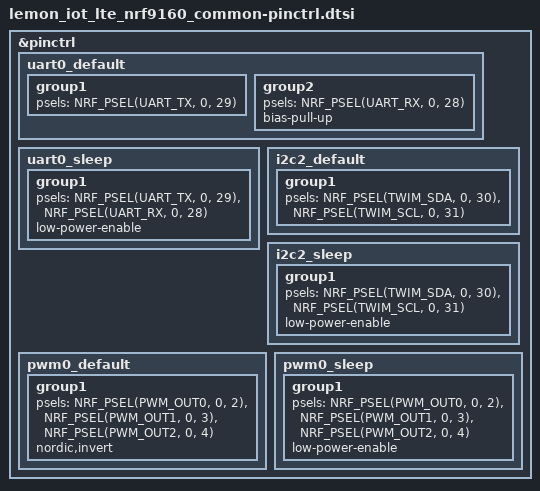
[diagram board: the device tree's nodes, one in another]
/*
 * Copyright (c) 2022-2023 Aaron Mohtar & Co Pty Ltd
 * Copyright (c) 2022 Nordic Semiconductor
 * SPDX-License-Identifier: Apache-2.0
 */

&pinctrl {
	uart0_default: uart0_default {
		group1 {
			psels = <NRF_PSEL(UART_TX, 0, 29)>;
		};
		group2 {
			psels = <NRF_PSEL(UART_RX, 0, 28)>;
			bias-pull-up;
		};
	};

	uart0_sleep: uart0_sleep {
		group1 {
			psels = <NRF_PSEL(UART_TX, 0, 29)>,
				<NRF_PSEL(UART_RX, 0, 28)>;
			low-power-enable;
		};
	};

	i2c2_default: i2c2_default {
		group1 {
			psels = <NRF_PSEL(TWIM_SDA, 0, 30)>,
				<NRF_PSEL(TWIM_SCL, 0, 31)>;
		};
	};

	i2c2_sleep: i2c2_sleep {
		group1 {
			psels = <NRF_PSEL(TWIM_SDA, 0, 30)>,
				<NRF_PSEL(TWIM_SCL, 0, 31)>;
			low-power-enable;
		};
	};

	pwm0_default: pwm0_default {
		group1 {
			psels = <NRF_PSEL(PWM_OUT0, 0, 2)>,
				<NRF_PSEL(PWM_OUT1, 0, 3)>,
				<NRF_PSEL(PWM_OUT2, 0, 4)>;
			nordic,invert;
		};
	};

	pwm0_sleep: pwm0_sleep {
		group1 {
			psels = <NRF_PSEL(PWM_OUT0, 0, 2)>,
				<NRF_PSEL(PWM_OUT1, 0, 3)>,
				<NRF_PSEL(PWM_OUT2, 0, 4)>;
			low-power-enable;
		};
	};
};
